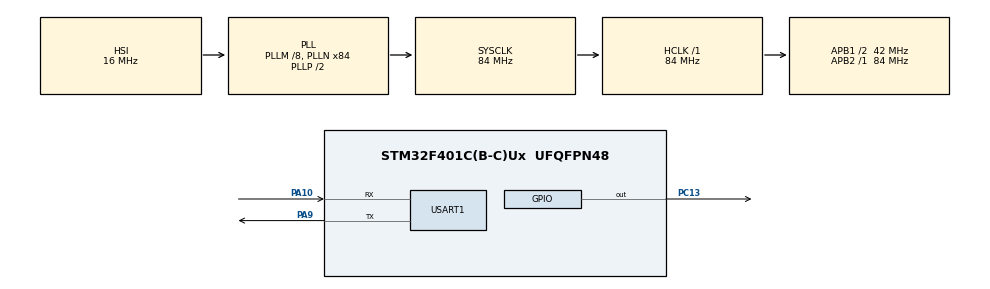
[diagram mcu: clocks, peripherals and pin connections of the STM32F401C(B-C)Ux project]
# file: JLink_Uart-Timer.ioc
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Mcu.Family=STM32F4
Mcu.Name=STM32F401C(B-C)Ux
Mcu.Package=UFQFPN48
NVIC.PriorityGroup=NVIC_PRIORITYGROUP_4
NVIC.TIM2_IRQn=true\:0\:0\:false\:false\:true\:true\:true\:true
NVIC.USART1_IRQn=true\:0\:0\:false\:false\:true\:true\:true\:true
PA10.Mode=Asynchronous
PA10.Signal=USART1_RX
PA13.Mode=JTAG_4_pins
PA13.Signal=SYS_JTMS-SWDIO
PA14.Mode=JTAG_4_pins
PA14.Signal=SYS_JTCK-SWCLK
PA15.Mode=JTAG_4_pins
PA15.Signal=SYS_JTDI
PA9.Mode=Asynchronous
PA9.Signal=USART1_TX
PB3.Mode=JTAG_4_pins
PB3.Signal=SYS_JTDO-SWO
PC13-ANTI_TAMP.Signal=GPIO_Output
PH0\ -\ OSC_IN.Mode=HSE-External-Oscillator
PH0\ -\ OSC_IN.Signal=RCC_OSC_IN
PH1\ -\ OSC_OUT.Mode=HSE-External-Oscillator
PH1\ -\ OSC_OUT.Signal=RCC_OSC_OUT
ProjectManager.HeapSize=0x200
ProjectManager.StackSize=0x400
ProjectManager.TargetToolchain=STM32CubeIDE
RCC.48MHZClocksFreq_Value=42000000
RCC.AHBFreq_Value=84000000
RCC.APB1CLKDivider=RCC_HCLK_DIV2
RCC.APB1Freq_Value=42000000
RCC.APB1TimFreq_Value=84000000
RCC.APB2Freq_Value=84000000
RCC.APB2TimFreq_Value=84000000
RCC.CortexFreq_Value=84000000
RCC.HCLKFreq_Value=84000000
RCC.HSE_VALUE=25000000
RCC.HSI_VALUE=16000000
RCC.LSE_VALUE=32768
RCC.PLLM=8
RCC.PLLN=84
RCC.SYSCLKFreq_VALUE=84000000
RCC.SYSCLKSource=RCC_SYSCLKSOURCE_PLLCLK
RCC.VCOOutputFreq_Value=168000000
TIM2.Period=1999
TIM2.Prescaler=41999
USART1.VirtualMode=VM_ASYNC
VP_TIM2_VS_ClockSourceINT.Mode=Internal
board=custom

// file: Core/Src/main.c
/* USER CODE BEGIN Header */
/**
  ******************************************************************************
  * @file           : main.c
  * @brief          : Main program body
  ******************************************************************************
  * @attention
  *
  * Copyright (c) 2024 STMicroelectronics.
  * All rights reserved.
  *
  * This software is licensed under terms that can be found in the LICENSE file
  * in the root directory of this software component.
  * If no LICENSE file comes with this software, it is provided AS-IS.
  *
  ******************************************************************************
  */
/* USER CODE END Header */
#include "main.h"

/* USER CODE BEGIN Includes */
#include <stdio.h>
#include <string.h>
/* USER CODE END Includes */

/* USER CODE BEGIN PD */
#define BUFFER_SIZE 50
/* USER CODE END PD */

TIM_HandleTypeDef htim2;

UART_HandleTypeDef huart1;

/* USER CODE BEGIN PV */
uint8_t recv_buf[1];
char *send_str = "Hello Kitty \r\n";

uint8_t u8_RxBuff[BUFFER_SIZE];
uint8_t u8_RxData;
uint8_t _rxIdx;
uint16_t Tx_Flag = 0;
uint8_t u8_TxBuff[BUFFER_SIZE];

/* USER CODE END PV */

void SystemClock_Config(void);
static void MX_GPIO_Init(void);
static void MX_TIM2_Init(void);
static void MX_USART1_UART_Init(void);

int main(void)
{

  /* MCU Configuration--------------------------------------------------------*/

  /* Reset of all peripherals, Initializes the Flash interface and the Systick. */
  HAL_Init();

  /* Configure the system clock */
  SystemClock_Config();

  /* Initialize all configured peripherals */
  MX_GPIO_Init();
  MX_TIM2_Init();
  MX_USART1_UART_Init();
  /* USER CODE BEGIN 2 */
  HAL_TIM_Base_Start_IT(&htim2);
  HAL_UART_Receive_IT(&huart1, recv_buf, 1);
  HAL_UART_Receive_IT(&huart1, &u8_RxData, 1);
  HAL_UART_Transmit(&huart1, (uint8_t *) send_str, strlen(send_str), 10);
  /* USER CODE END 2 */

  /* Infinite loop */
  while (1)
  {

    /* USER CODE BEGIN 3 */
	  if(Tx_Flag)
	  {
		  for(int index = 0; index < BUFFER_SIZE; index++)
		  {
			  u8_TxBuff[index] = u8_RxBuff[index];
		  }
		  HAL_UART_Transmit(&huart1, u8_TxBuff, sizeof(u8_TxBuff), 100);
		  memset(u8_RxBuff, 0, sizeof(u8_RxBuff));
		  Tx_Flag = 0;
	  }

  }
  /* USER CODE END 3 */
}

void SystemClock_Config(void)
{
  RCC_OscInitTypeDef RCC_OscInitStruct = {0};
  RCC_ClkInitTypeDef RCC_ClkInitStruct = {0};

  /** Configure the main internal regulator output voltage
  */
  __HAL_RCC_PWR_CLK_ENABLE();
  __HAL_PWR_VOLTAGESCALING_CONFIG(PWR_REGULATOR_VOLTAGE_SCALE2);

  /** Initializes the RCC Oscillators according to the specified parameters
  * in the RCC_OscInitTypeDef structure.
  */
  RCC_OscInitStruct.OscillatorType = RCC_OSCILLATORTYPE_HSI;
  RCC_OscInitStruct.HSIState = RCC_HSI_ON;
  RCC_OscInitStruct.HSICalibrationValue = RCC_HSICALIBRATION_DEFAULT;
  RCC_OscInitStruct.PLL.PLLState = RCC_PLL_ON;
  RCC_OscInitStruct.PLL.PLLSource = RCC_PLLSOURCE_HSI;
  RCC_OscInitStruct.PLL.PLLM = 8;
  RCC_OscInitStruct.PLL.PLLN = 84;
  RCC_OscInitStruct.PLL.PLLP = RCC_PLLP_DIV2;
  RCC_OscInitStruct.PLL.PLLQ = 4;
  if (HAL_RCC_OscConfig(&RCC_OscInitStruct) != HAL_OK)
  {
    Error_Handler();
  }

  /** Initializes the CPU, AHB and APB buses clocks
  */
  RCC_ClkInitStruct.ClockType = RCC_CLOCKTYPE_HCLK|RCC_CLOCKTYPE_SYSCLK
                              |RCC_CLOCKTYPE_PCLK1|RCC_CLOCKTYPE_PCLK2;
  RCC_ClkInitStruct.SYSCLKSource = RCC_SYSCLKSOURCE_PLLCLK;
  RCC_ClkInitStruct.AHBCLKDivider = RCC_SYSCLK_DIV1;
  RCC_ClkInitStruct.APB1CLKDivider = RCC_HCLK_DIV2;
  RCC_ClkInitStruct.APB2CLKDivider = RCC_HCLK_DIV1;

  if (HAL_RCC_ClockConfig(&RCC_ClkInitStruct, FLASH_LATENCY_2) != HAL_OK)
  {
    Error_Handler();
  }
}

static void MX_TIM2_Init(void)
{

  TIM_ClockConfigTypeDef sClockSourceConfig = {0};
  TIM_MasterConfigTypeDef sMasterConfig = {0};

  htim2.Instance = TIM2;
  htim2.Init.Prescaler = 41999;
  htim2.Init.CounterMode = TIM_COUNTERMODE_UP;
  htim2.Init.Period = 1999;
  htim2.Init.ClockDivision = TIM_CLOCKDIVISION_DIV1;
  htim2.Init.AutoReloadPreload = TIM_AUTORELOAD_PRELOAD_DISABLE;
  if (HAL_TIM_Base_Init(&htim2) != HAL_OK)
  {
    Error_Handler();
  }
  sClockSourceConfig.ClockSource = TIM_CLOCKSOURCE_INTERNAL;
  if (HAL_TIM_ConfigClockSource(&htim2, &sClockSourceConfig) != HAL_OK)
  {
    Error_Handler();
  }
  sMasterConfig.MasterOutputTrigger = TIM_TRGO_RESET;
  sMasterConfig.MasterSlaveMode = TIM_MASTERSLAVEMODE_DISABLE;
  if (HAL_TIMEx_MasterConfigSynchronization(&htim2, &sMasterConfig) != HAL_OK)
  {
    Error_Handler();
  }

}

static void MX_USART1_UART_Init(void)
{

  huart1.Instance = USART1;
  huart1.Init.BaudRate = 115200;
  huart1.Init.WordLength = UART_WORDLENGTH_8B;
  huart1.Init.StopBits = UART_STOPBITS_1;
  huart1.Init.Parity = UART_PARITY_NONE;
  huart1.Init.Mode = UART_MODE_TX_RX;
  huart1.Init.HwFlowCtl = UART_HWCONTROL_NONE;
  huart1.Init.OverSampling = UART_OVERSAMPLING_16;
  if (HAL_UART_Init(&huart1) != HAL_OK)
  {
    Error_Handler();
  }

}

static void MX_GPIO_Init(void)
{
  GPIO_InitTypeDef GPIO_InitStruct = {0};

  /* GPIO Ports Clock Enable */
  __HAL_RCC_GPIOC_CLK_ENABLE();
  __HAL_RCC_GPIOH_CLK_ENABLE();
  __HAL_RCC_GPIOA_CLK_ENABLE();
  __HAL_RCC_GPIOB_CLK_ENABLE();

  /*Configure GPIO pin Output Level */
  HAL_GPIO_WritePin(GPIOC, GPIO_PIN_13, GPIO_PIN_RESET);

  /*Configure GPIO pin : PC13 */
  GPIO_InitStruct.Pin = GPIO_PIN_13;
  GPIO_InitStruct.Mode = GPIO_MODE_OUTPUT_PP;
  GPIO_InitStruct.Pull = GPIO_NOPULL;
  GPIO_InitStruct.Speed = GPIO_SPEED_FREQ_LOW;
  HAL_GPIO_Init(GPIOC, &GPIO_InitStruct);

}

/* USER CODE BEGIN 4 */
void HAL_TIM_PeriodElapsedCallback(TIM_HandleTypeDef *htim)
{
	if(htim->Instance == TIM2)
	{
		HAL_GPIO_TogglePin(GPIOC, GPIO_PIN_13);
	}
}
void HAL_UART_RxCpltCallback(UART_HandleTypeDef *huart)
{
	if(huart->Instance == USART1)
	{
		/* Callback handler written below */
		if(u8_RxData != 13)  //NULL ASCII
			u8_RxBuff[_rxIdx++] = u8_RxData; //add Rxdata to RxBuffer
		else if(u8_RxData == 13)
		{
			_rxIdx = 0;
			Tx_Flag = 1;
		}
		//HAL_UART_Transmit(&huart1, (uint8_t *)&recv_buf, 1, 10);
		HAL_UART_Receive_IT(&huart1, &u8_RxData, 1);
	}
}

/* USER CODE END 4 */

void Error_Handler(void)
{
  __disable_irq();
  while (1)
  {
  }
}
